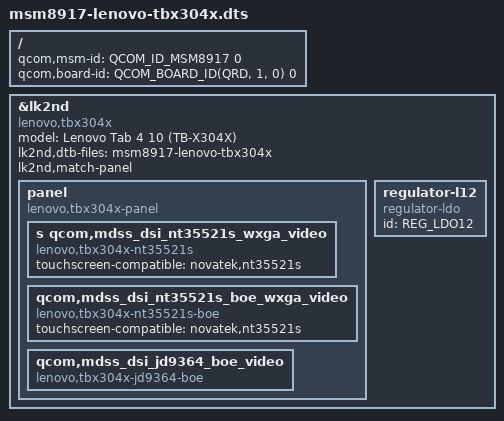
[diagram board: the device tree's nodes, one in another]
// SPDX-License-Identifier: BSD-3-Clause
/dts-v1/;
#include <skeleton64.dtsi>
#include <lk2nd.dtsi>
#include <dt-bindings/lk2nd/regulator.h>

/ {
	qcom,msm-id = <QCOM_ID_MSM8917 0>;
	qcom,board-id = <QCOM_BOARD_ID(QRD, 1, 0) 0>;
};

&lk2nd {
	model = "Lenovo Tab 4 10 (TB-X304X)";
	compatible = "lenovo,tbx304x";

	lk2nd,dtb-files = "msm8917-lenovo-tbx304x";
	lk2nd,match-panel;

	panel {
		compatible = "lenovo,tbx304x-panel", "lk2nd,panel";s

		qcom,mdss_dsi_nt35521s_wxga_video {
			compatible = "lenovo,tbx304x-nt35521s";
			touchscreen-compatible = "novatek,nt35521s";
		};

		qcom,mdss_dsi_nt35521s_boe_wxga_video {
			compatible = "lenovo,tbx304x-nt35521s-boe";
			touchscreen-compatible = "novatek,nt35521s";
		};

		qcom,mdss_dsi_jd9364_boe_video {
			compatible = "lenovo,tbx304x-jd9364-boe";
		};
	};

	regulator-l12 {
		compatible = "regulator-ldo";
		id = <REG_LDO12>;
	};
};
